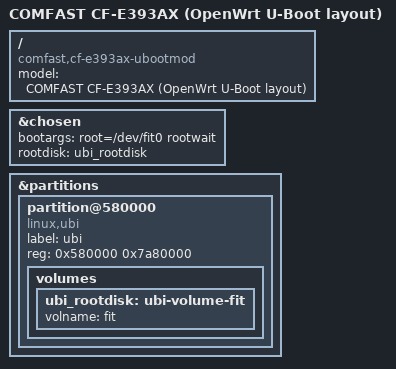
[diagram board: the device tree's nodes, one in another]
// SPDX-License-Identifier: GPL-2.0-or-later OR MIT

/dts-v1/;
#include "mt7981a-comfast-cf-e393ax.dtsi"

/ {
    model = "COMFAST CF-E393AX (OpenWrt U-Boot layout)";
    compatible = "comfast,cf-e393ax-ubootmod", "mediatek,mt7981";
};

&chosen {
	bootargs = "root=/dev/fit0 rootwait";
	rootdisk = <&ubi_rootdisk>;
};

&partitions {
	partition@580000 {
		compatible = "linux,ubi";
		label = "ubi";
		reg = <0x580000 0x7a80000>;

		volumes {
			ubi_rootdisk: ubi-volume-fit {
				volname = "fit";
			};
		};
	};
};

